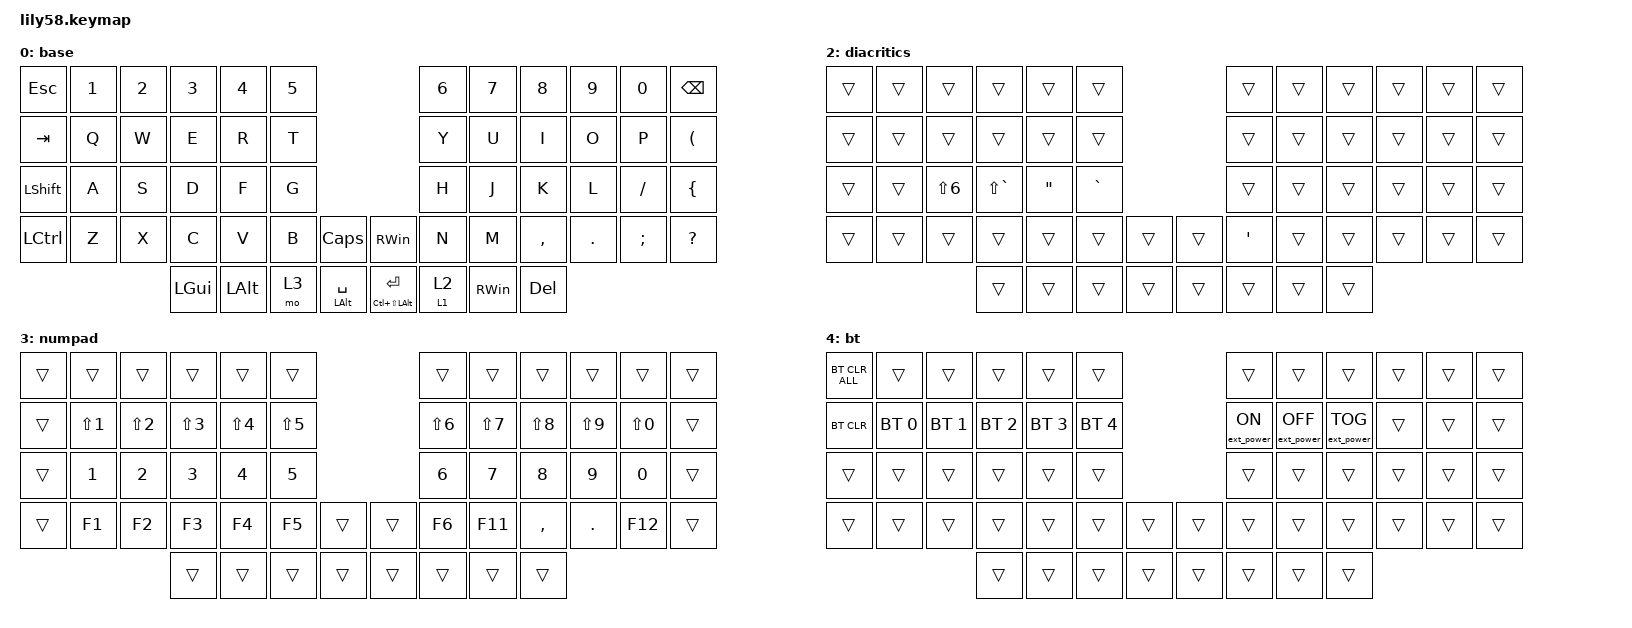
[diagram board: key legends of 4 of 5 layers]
/*
 * Copyright (c) 2020 The ZMK Contributors
 *
 * SPDX-License-Identifier: MIT
 */

#include <behaviors.dtsi>
#include <dt-bindings/zmk/bt.h>
#include <dt-bindings/zmk/ext_power.h>
#include <dt-bindings/zmk/keys.h>

&mt { flavor = "balanced"; };

/ {
    behaviors {
        hold_tap_layer: hold_tap_layer {
            compatible = "zmk,behavior-hold-tap";
            label = "HOLD_TAP_LAYER";
            bindings = <&mo>, <&sl>;

            #binding-cells = <2>;
            tapping-term-ms = <200>;
            flavor = "balanced";
        };
    };

    combos {
        compatible = "zmk,combos";

        r_backspace {
            bindings = <&kp BACKSPACE>;
            key-positions = <20 21>;
        };

        r_delete {
            bindings = <&kp DELETE>;
            key-positions = <46 47>;
        };

        l_backspace {
            bindings = <&kp BACKSPACE>;
            key-positions = <14 15>;
        };

        l_delete {
            bindings = <&kp DELETE>;
            key-positions = <38 39>;
        };

        l_tab {
            bindings = <&kp TAB>;
            key-positions = <16 29>;
        };

        r_tab {
            bindings = <&kp TAB>;
            key-positions = <18 19>;
        };

        esc {
            bindings = <&kp ESC>;
            key-positions = <13 14>;
        };

        caps {
            bindings = <&caps_word>;
            key-positions = <29 30>;
        };

        r_bkspc_word {
            bindings = <&kp LC(BACKSPACE)>;
            key-positions = <20 21 19>;
        };

        l_bkspc_word {
            bindings = <&kp LC(BACKSPACE)>;
            key-positions = <14 15 16>;
        };

        r_delete_word {
            bindings = <&kp LC(DELETE)>;
            key-positions = <45 46 47>;
        };

        l_delete_word {
            bindings = <&kp LC(DELETE)>;
            key-positions = <40 39 38>;
        };
    };

    macros {
        single_quotes: single_quotes {
            compatible = "zmk,behavior-macro";
            #binding-cells = <0>;
            bindings = <&kp SQT &kp SPACE>;
            label = "SINGLE_QUOTES";
        };

        double_quotes: double_quotes {
            compatible = "zmk,behavior-macro";
            #binding-cells = <0>;
            bindings = <&kp DQT &kp SPACE>;
            label = "DOUBLE_QUOTES";
        };

        backtick: backtick {
            compatible = "zmk,behavior-macro";
            #binding-cells = <0>;
            bindings = <&none &kp GRAVE &kp SPACE>;
            label = "BACKTICK";
        };
    };

    keymap {
        compatible = "zmk,keymap";

        base {
            // ------------------------------------------------------------------------------------------------------------
            // |  ESC  |  1  |  2  |  3   |  4   |  5   |                   |  6   |  7    |  8    |  9   |   0   |   `   |
            // |  TAB  |  Q  |  W  |  E   |  R   |  T   |                   |  Y   |  U    |  I    |  O   |   P   |   -   |
            // | CTRL   |A  |  S  |  D   |  F   |  G   |                   |  H   |  J    |  K    |  L   |   ;   |   '   |
            // | SHIFT |  Z  |  X  |  C   |  V   |  B   |   "["  |  |  "]"  |  N   |  M    |  ,    |  .   |   /   | SHIFT |
            //                     | ALT  | GUI  | LOWER|  SPACE |  | BSPC  | RAISE| ENTER | GUI   |

            bindings = <
&kp ESC    &kp N1  &kp N2  &kp N3    &kp N4        &kp N5                                                  &kp N6               &kp N7         &kp N8      &kp N9      &kp N0    &kp BACKSPACE
&kp TAB    &kp Q   &kp W   &kp E     &kp R         &kp T                                                   &kp Y                &kp U          &kp I       &kp O       &kp P     &kp LEFT_PARENTHESIS
&kp LSHFT  &kp A   &kp S   &kp D     &kp F         &kp G                                                   &kp H                &kp J          &kp K       &kp L       &kp FSLH  &kp LEFT_BRACE
&kp LCTRL  &kp Z   &kp X   &kp C     &kp V         &kp B   &kp CAPSLOCK        &kp RIGHT_WIN               &kp N                &kp M          &kp COMMA   &kp PERIOD  &kp SEMI  &kp QUESTION
                           &kp LGUI  &kp LEFT_ALT  &mo 3   &mt LEFT_ALT SPACE  &mt LC(LS(LEFT_ALT)) ENTER  &hold_tap_layer 1 2  &kp RIGHT_WIN  &kp DELETE
            >;

            sensor-bindings = <&inc_dec_kp DOWN UP &inc_dec_kp LC(TAB) LC(LS(TAB))>;
        };

        symbols {
            // ------------------------------------------------------------------------------------------------------------
            // | BTCLR | BT1 | BT2 |  BT3 |  BT4 |  BT5 |                   |      |       |       |      |       |       |
            // |  F1   |  F2 |  F3 |  F4  |  F5  |  F6  |                   |  F7  |  F8   |  F9   |  F10 |  F11  |  F12  |
            // |   `   |  !  |  @  |  #   |  $   |  %   |                   |  ^   |  &    |  *    |  (   |   )   |   ~   |
            // |   |  |  |  | |      |      |  |      |       |  _    |  +   |  {    |   }   |  "|"  |
            //                     |      |      |      |        |  |       |      |       |       |

            bindings = <
&trans  &trans           &trans          &trans            &trans                 &trans                     &kp C_PREV      &kp C_PLAY_PAUSE  &kp C_NEXT      &kp C_BRIGHTNESS_DEC  &kp C_BRIGHTNESS_INC  &trans
&trans  &kp PRINTSCREEN  &kp UP_ARROW    &kp LEFT_BRACE    &kp RIGHT_BRACE        &kp PLUS                   &backtick       &kp PLUS          &trans          &trans                &kp KP_EQUAL          &kp RIGHT_PARENTHESIS
&trans  &kp LEFT_ARROW   &kp DOWN_ARROW  &kp RIGHT_ARROW   &kp RIGHT_PARENTHESIS  &kp MINUS                  &single_quotes  &kp LEFT          &kp UP_ARROW    &kp DOWN              &kp RIGHT             &kp RIGHT_BRACE
&trans  &trans           &trans          &kp LEFT_BRACKET  &kp RIGHT_BRACKET      &kp UNDER  &trans  &trans  &double_quotes  &kp PIPE          &kp LEFT_BRACE  &kp RIGHT_BRACE       &kp BACKSLASH         &trans
                                         &trans            &trans                 &trans     &trans  &trans  &trans          &trans
            >;
        };

        diacritics {
            // ------------------------------------------------------------------------------------------------------------
            // |       |     |     |      |      |      |                   |      |       |       |      |       |       |
            // |   `   |  1  |  2  |  3   |  4   |  5   |                   |  6   |   7   |   8   |  9   |   0   |       |
            // |   F1  |  F2 |  F3 |  F4  |  F5  |  F6  |                   |  <-  |   v   |  ^    |  ->  |       |       |
            // |   F7  |  F8 |  F9 |  F10 |  F11 |  F12 |        |  |       |  +   |   -   |   =   |  [   |   ]   |   \   |
            //                     |      |      |      |        |  |       |      |       |       |

            bindings = <
&trans  &trans  &trans            &trans         &trans             &trans                     &trans    &trans  &trans  &trans  &trans  &trans
&trans  &trans  &trans            &trans         &trans             &trans                     &trans    &trans  &trans  &trans  &trans  &trans
&trans  &trans  &kp LS(NUMBER_6)  &kp LS(GRAVE)  &kp DOUBLE_QUOTES  &kp GRAVE                  &trans    &trans  &trans  &trans  &trans  &trans
&trans  &trans  &trans            &trans         &trans             &trans     &trans  &trans  &kp APOS  &trans  &trans  &trans  &trans  &trans
                                  &trans         &trans             &trans     &trans  &trans  &trans    &trans  &trans
            >;
        };

        numpad {
            bindings = <
&trans  &trans            &trans            &trans            &trans            &trans                      &trans            &trans      &trans      &trans      &trans      &trans
&trans  &kp LS(NUMBER_1)  &kp LS(NUMBER_2)  &kp LS(NUMBER_3)  &kp LS(NUMBER_4)  &kp LS(N5)                  &kp LS(NUMBER_6)  &kp LS(N7)  &kp LS(N8)  &kp LS(N9)  &kp LS(N0)  &trans
&trans  &kp NUMBER_1      &kp NUMBER_2      &kp NUMBER_3      &kp NUMBER_4      &kp N5                      &kp NUMBER_6      &kp N7      &kp N8      &kp N9      &kp N0      &trans
&trans  &kp F1            &kp F2            &kp F3            &kp F4            &kp F5      &trans  &trans  &kp F6            &kp F11     &kp COMMA   &kp PERIOD  &kp F12     &trans
                                            &trans            &trans            &trans      &trans  &trans  &trans            &trans      &trans
            >;
        };

        bt {
            bindings = <
&bt BT_CLR_ALL  &trans        &trans        &trans        &trans        &trans                        &trans            &trans             &trans             &trans  &trans  &trans
&bt BT_CLR      &bt BT_SEL 0  &bt BT_SEL 1  &bt BT_SEL 2  &bt BT_SEL 3  &bt BT_SEL 4                  &ext_power EP_ON  &ext_power EP_OFF  &ext_power EP_TOG  &trans  &trans  &trans
&trans          &trans        &trans        &trans        &trans        &trans                        &trans            &trans             &trans             &trans  &trans  &trans
&trans          &trans        &trans        &trans        &trans        &trans        &trans  &trans  &trans            &trans             &trans             &trans  &trans  &trans
                                            &trans        &trans        &trans        &trans  &trans  &trans            &trans             &trans
            >;
        };
    };

    conditional_layers {
        compatible = "zmk,conditional-layers";

        bt {
            if-layers = <1 3>;
            then-layer = <4>;
        };
    };
};
